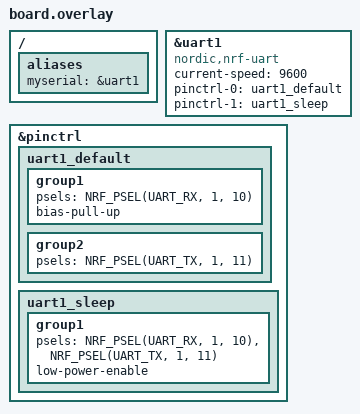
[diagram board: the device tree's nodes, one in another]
/ {
    aliases {
        myserial = &uart1;
    };
};

// &uart0 {
//     status = "disabled";
// };

arduino_serial: &uart1 {
    status = "okay";
    compatible = "nordic,nrf-uart";
	current-speed = <9600>;
	pinctrl-0 = <&uart1_default>;
	pinctrl-1 = <&uart1_sleep>;
	pinctrl-names = "default", "sleep";
};

&pinctrl {
	uart1_default: uart1_default {
		group1 {
			psels = <NRF_PSEL(UART_RX, 1, 10)>;
			bias-pull-up;
		};
		group2 {
			psels = <NRF_PSEL(UART_TX, 1, 11)>;
		};
	};

	uart1_sleep: uart1_sleep {
		group1 {
			psels = <NRF_PSEL(UART_RX, 1, 10)>,
				<NRF_PSEL(UART_TX, 1, 11)>;
			low-power-enable;
		};
	};
};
